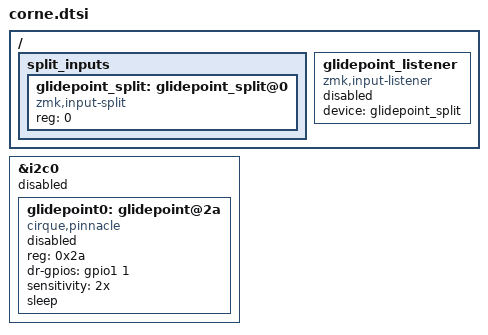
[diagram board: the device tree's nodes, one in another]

/* cirque trackpad I2C pins */
/* See: https://zmk.dev/docs/development/hardware-integration/pointing?part-type=peripheral#input-device */

/* trick: adds the device as "disabled" to easily swap central/peripheral roles */
&i2c0 {
    status = "disabled";
    glidepoint0: glidepoint@2a {                          // glidepoint0 = central, glidepoint1 = peripheral
        compatible = "cirque,pinnacle";
        reg = <0x2a>;                                     // default slave address
        status = "disabled";
        dr-gpios = <&gpio1 1 (GPIO_ACTIVE_HIGH)>;         // P1.01 (maybe it is P1.02)

        sensitivity = "2x";
        sleep;
        //no-taps;

        // see: https://github.com/petejohanson/cirque-input-module/blob/main/dts/bindings/input/cirque%2Cpinnacle-common.yaml
        //rotate-90 = false;
        //x-invert = false;
        //y-invert = false;
        //sleep = false;
        //no-secondary-tap = false;
        //no-taps = false;
        //sensitivity = 1x | 2x | 3x | 4x
        //x-axis-z-min = 5;
        //y-axis-z-min= 4;
    };
};


/* See: https://zmk.dev/docs/development/hardware-integration/pointing?part-type=peripheral#shared-configuration-1 */
/ {
    split_inputs {
        #address-cells = <1>;
        #size-cells = <0>;

        glidepoint_split: glidepoint_split@0 {
            compatible = "zmk,input-split";
            reg = <0>;
        };
    };

    glidepoint_listener: glidepoint_listener {
        compatible = "zmk,input-listener";
        status = "disabled";
        device = <&glidepoint_split>;
    };
};
